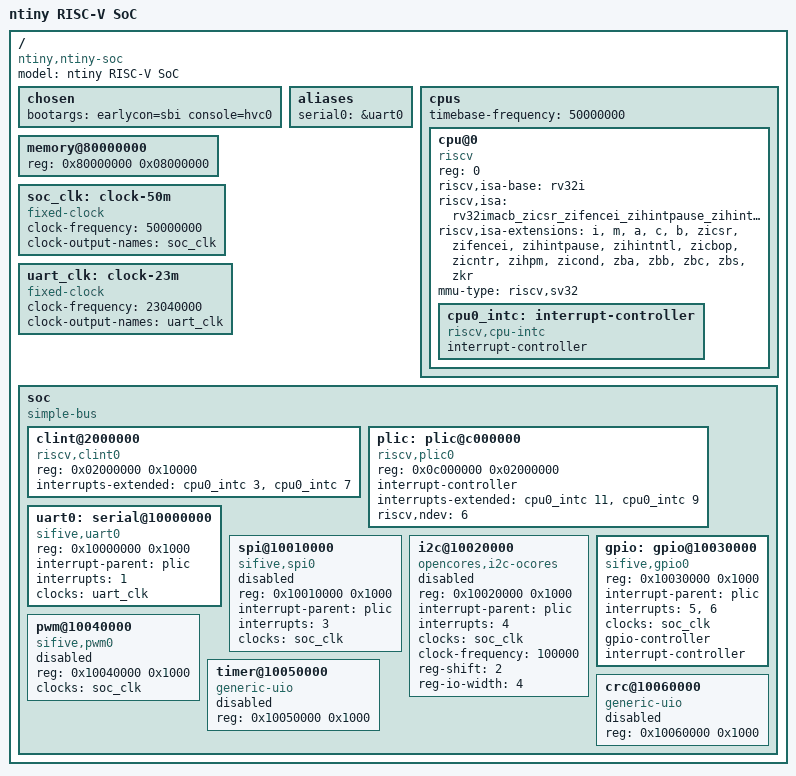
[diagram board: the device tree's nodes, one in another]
/dts-v1/;

/*
 * ntiny RISC-V SoC devicetree.
 *
 * Phase 1 of the peripheral-standardisation plan
 * (docs/peripheral_standardization_plan.md): peripheral nodes use the
 * upstream Linux IP "compatible" strings (sifive,uart0/gpio0/spi0/pwm,
 * opencores,i2c-ocores) so the in-tree kernel drivers will probe.
 *
 * Until the matching Phase 2 RTL refactors land, peripheral nodes
 * are marked status="disabled" so the matching drivers don't probe.
 * Each Phase 2 step flips its peripheral's status to "okay" once
 * RTL + bare-metal driver are refactored in lockstep.
 *
 * (PLIC S-mode context is also a prerequisite — current PLIC HW has
 * M-mode context only [opensbi platform.c context_map [0] = {0,-1}],
 * which means Linux running in S-mode crashes inside plic_irq_enable
 * the moment any driver requests an IRQ. Adding the S-mode context
 * to the PLIC RTL is its own pre-Phase-2 task.)
 *
 * HVC-over-SBI remains the active console throughout.
 *
 * Memory map (matches design/interconnect/src/addr_decoder.sv):
 *   0x10000000  UART
 *   0x10010000  SPI
 *   0x10020000  I2C
 *   0x10030000  GPIO
 *   0x10040000  PWM
 *   0x10050000  TIMER  (will be dropped Phase 3 — CLINT covers OS tick)
 *   0x10060000  CRC
 *   0x02000000  CLINT
 *   0x0C000000  PLIC   (6 sources: 1=uart_rx, 2=uart_tx, 3=spi,
 *                       4=i2c, 5=gpio[0], 6=gpio[1])
 *   0x80000000  RAM
 */

/ {
    #address-cells = <1>;
    #size-cells = <1>;
    compatible = "ntiny,ntiny-soc";
    model = "ntiny RISC-V SoC";

    chosen {
        bootargs = "earlycon=sbi console=hvc0";
    };

    /* SiFive UART driver requires aliases entry for tty index assignment;
     * without it tty_register_device is skipped and /dev/ttyS0 never
     * appears. */
    aliases {
        serial0 = &uart0;
    };

    cpus {
        #address-cells = <1>;
        #size-cells = <0>;
        timebase-frequency = <50000000>;

        cpu@0 {
            device_type = "cpu";
            reg = <0>;
            compatible = "riscv";
            riscv,isa-base = "rv32i";
            riscv,isa = "rv32imacb_zicsr_zifencei_zihintpause_zihintntl_zicbop_zicntr_zihpm_zicond_zba_zbb_zbc_zbs_zkr";
            riscv,isa-extensions = "i", "m", "a", "c", "b", "zicsr", "zifencei", "zihintpause", "zihintntl", "zicbop", "zicntr", "zihpm", "zicond", "zba", "zbb", "zbc", "zbs", "zkr";
            mmu-type = "riscv,sv32";

            cpu0_intc: interrupt-controller {
                #interrupt-cells = <1>;
                interrupt-controller;
                compatible = "riscv,cpu-intc";
            };
        };
    };

    memory@80000000 {
        device_type = "memory";
        reg = <0x80000000 0x08000000>;  /* 128 MB */
    };

    /* Single fixed clock — the SoC runs everything off one 50 MHz
     * domain. SiFive + OpenCores drivers all need a clock handle. */
    soc_clk: clock-50m {
        compatible = "fixed-clock";
        #clock-cells = <0>;
        clock-frequency = <50000000>;
        clock-output-names = "soc_clk";
    };

    /* "Lying" UART clock node. The SiFive serial driver computes
     *   div = uartclk / baud - 1
     * and writes div on probe, using SIFIVE_DEFAULT_BAUD_RATE = 115200.
     * To get div = 199 (matches the testbench uartdpi BAUD = 250000
     * + OpenSBI's matching value) without slowing the actual TX rate,
     * we tell the driver the clock is 23.04 MHz: 23.04M / 115200 - 1
     * = 199. The hardware itself still runs at 50 MHz; this fiction
     * is purely so the SiFive driver doesn't reprogram div=433 and
     * corrupt the UART after probe. */
    uart_clk: clock-23m {
        compatible = "fixed-clock";
        #clock-cells = <0>;
        clock-frequency = <23040000>;
        clock-output-names = "uart_clk";
    };

    soc {
        #address-cells = <1>;
        #size-cells = <1>;
        compatible = "simple-bus";
        ranges;

        clint@2000000 {
            compatible = "riscv,clint0";
            reg = <0x02000000 0x10000>;
            interrupts-extended = <&cpu0_intc 3>, <&cpu0_intc 7>;
        };

        plic: plic@c000000 {
            compatible = "riscv,plic0";
            reg = <0x0c000000 0x02000000>;
            #interrupt-cells = <1>;
            interrupt-controller;
            /* Two contexts per hart: M-mode (IRQ 11) + S-mode (IRQ 9).
             * Linux PLIC driver registers a handler per context. */
            interrupts-extended = <&cpu0_intc 11>, <&cpu0_intc 9>;
            riscv,ndev = <6>;
        };

        /* UART0 — sifive,uart0 (Phase 2b: RTL refactored to match).
         * The HVC console keeps going through OpenSBI (no Linux UART
         * driver involved). With this node enabled, the SiFive driver
         * additionally probes and exposes /dev/ttySIF0 — the boot
         * test script will report uart.driver PASS once it appears. */
        uart0: serial@10000000 {
            compatible = "sifive,uart0";
            reg = <0x10000000 0x1000>;
            interrupt-parent = <&plic>;
            interrupts = <1>;          /* uart_rx */
            clocks = <&uart_clk>;      /* lying clock — see clock-23m comment */
        };

        /* SPI0 — target sifive,spi0 (Phase 2d). */
        spi@10010000 {
            compatible = "sifive,spi0";
            reg = <0x10010000 0x1000>;
            interrupt-parent = <&plic>;
            interrupts = <3>;
            clocks = <&soc_clk>;
            #address-cells = <1>;
            #size-cells = <0>;
            status = "disabled";
        };

        /* I2C0 — opencores,i2c-ocores (Phase 2c: RTL refactored to
         * the upstream layout — prelo/prehi at 0x00/0x04, ctrl at
         * 0x08, tx/rx aliased on 0x0C, cmd/status aliased on 0x10).
         * DT keeps status="disabled": enabling the node currently
         * triggers a layout-sensitive get_page_from_freelist NULL
         * deref in init (or a sysctl hang depending on LEGACY_PTYS).
         * The RTL refactor itself is correct (bare-metal peek/poke
         * passes); only the Linux driver enablement is parked
         * pending a separate kernel-side debug session. */
        i2c@10020000 {
            compatible = "opencores,i2c-ocores";
            reg = <0x10020000 0x1000>;
            interrupt-parent = <&plic>;
            interrupts = <4>;
            clocks = <&soc_clk>;
            clock-frequency = <100000>;
            reg-shift = <2>;
            reg-io-width = <4>;
            #address-cells = <1>;
            #size-cells = <0>;
            status = "disabled";
        };

        /* GPIO — sifive,gpio0 (Phase 2a, RTL refactored to match). The
         * Linux driver derives ngpio from the count of "interrupts"
         * entries: ntiny exposes 2 IRQ-capable pins (gpio[0], gpio[1]),
         * so Linux sees a 2-pin gpiochip. The other 30 pins still work
         * for I/O via direct register access; full 32-IRQ matrix is a
         * later sub-step (Phase 2a-ext). */
        gpio: gpio@10030000 {
            compatible = "sifive,gpio0";
            reg = <0x10030000 0x1000>;
            interrupt-parent = <&plic>;
            interrupts = <5>, <6>;
            clocks = <&soc_clk>;
            #gpio-cells = <2>;
            gpio-controller;
            #interrupt-cells = <2>;
            interrupt-controller;
        };

        /* PWM — target sifive,pwm0 (Phase 2e). No PWM IRQs wired in
         * RTL today; driver will fall back to non-IRQ mode. */
        pwm@10040000 {
            compatible = "sifive,pwm0";
            reg = <0x10040000 0x1000>;
            clocks = <&soc_clk>;
            #pwm-cells = <3>;
            status = "disabled";
        };

        /* TIMER — to be dropped Phase 3 (CLINT mtime covers OS tick). */
        timer@10050000 {
            compatible = "generic-uio";
            reg = <0x10050000 0x1000>;
            status = "disabled";
        };

        /* CRC — exposed via UIO for userspace mmap (Phase 3). */
        crc@10060000 {
            compatible = "generic-uio";
            reg = <0x10060000 0x1000>;
            status = "disabled";
        };
    };
};
